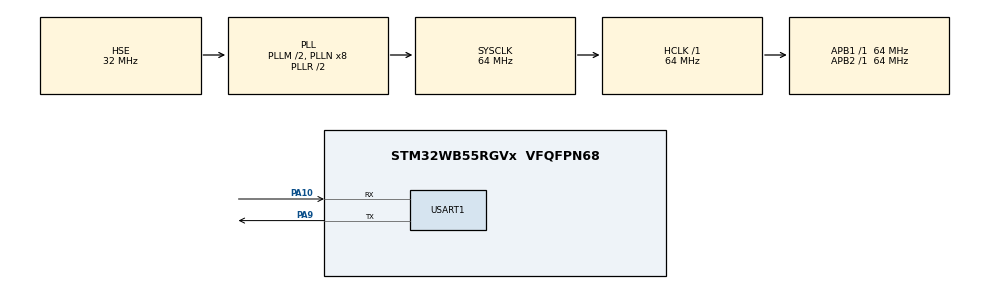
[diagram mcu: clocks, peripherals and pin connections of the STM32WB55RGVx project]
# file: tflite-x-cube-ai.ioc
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Mcu.Family=STM32WB
Mcu.Name=STM32WB55RGVx
Mcu.Package=VFQFPN68
NVIC.PriorityGroup=NVIC_PRIORITYGROUP_4
OSC_IN.GPIO_Label=RCC_OSC_IN
OSC_IN.Mode=HSE-External-Oscillator
OSC_IN.Signal=RCC_OSC_IN
OSC_OUT.GPIO_Label=RCC_OSC_OUT
OSC_OUT.Mode=HSE-External-Oscillator
OSC_OUT.Signal=RCC_OSC_OUT
P-NUCLEO-WB55-NUCLEO.BUTTON=1
P-NUCLEO-WB55-NUCLEO.BUTTON2=1
P-NUCLEO-WB55-NUCLEO.BUTTON3=1
P-NUCLEO-WB55-NUCLEO.LD1=true
P-NUCLEO-WB55-NUCLEO.LD2=true
P-NUCLEO-WB55-NUCLEO.LD3=true
P-NUCLEO-WB55-NUCLEO.VCP=false
PA10.Mode=Asynchronous
PA10.Signal=USART1_RX
PA11.GPIO_Label=USB_DM
PA11.Signal=USB_DM
PA12.GPIO_Label=USB_DP
PA12.Signal=USB_DP
PA13.GPIO_Label=JTMS
PA13.Signal=SYS_JTMS-SWDIO
PA14.GPIO_Label=JTCK
PA14.Signal=SYS_JTCK-SWCLK
PA9.Mode=Asynchronous
PA9.Signal=USART1_TX
PB3.GPIO_Label=JTDO
PB3.Signal=SYS_JTDO-SWO
PC13.GPIO_Label=SYS_WKUP2
PC13.Signal=SYS_WKUP2
PC14-OSC32_IN.GPIO_Label=RCC_OSC32_IN
PC14-OSC32_IN.Signal=RCC_OSC32_IN
PC15-OSC32_OUT.GPIO_Label=RCC_OSC32_OUT
PC15-OSC32_OUT.Signal=RCC_OSC32_OUT
ProjectManager.HeapSize=0x800
ProjectManager.StackSize=0x800
ProjectManager.TargetToolchain=STM32CubeIDE
RCC.ADCFreq_Value=64000000
RCC.AHB2CLKDivider=RCC_SYSCLK_DIV2
RCC.AHBFreq_Value=64000000
RCC.APB1Freq_Value=64000000
RCC.APB1TimFreq_Value=64000000
RCC.APB2Freq_Value=64000000
RCC.APB2TimFreq_Value=64000000
RCC.APB3Freq_Value=16000000
RCC.Cortex2_Div=SYSTICK_CLKSOURCE_HCLK_DIV8
RCC.CortexFreq_Value=64000000
RCC.HCLKFreq_Value=64000000
RCC.HSE_VALUE=32000000
RCC.HSI48_VALUE=48000000
RCC.HSI_VALUE=16000000
RCC.LPUART1CLockSelection=RCC_LPUART1CLKSOURCE_SYSCLK
RCC.LSE_VALUE=32768
RCC.MSIClockRange=RCC_MSIRANGE_10
RCC.PLLM=RCC_PLLM_DIV2
RCC.PLLSourceVirtual=RCC_PLLSOURCE_HSE
RCC.SMPSCLockSelection=RCC_SMPSCLKSOURCE_HSI
RCC.SMPSCLockSelectionVirtual=RCC_SMPSCLKSOURCE_HSI
RCC.SMPSCLockSelectionVirtualVirtual=RCC_SMPSCLKSOURCE_HSI
RCC.SMPSDivider=1
RCC.SYSCLKFreq_VALUE=64000000
RCC.SYSCLKSource=RCC_SYSCLKSOURCE_PLLCLK
RCC.USART1CLockSelection=RCC_USART1CLKSOURCE_SYSCLK
RCC.USBFreq_Value=64000000
RCC.VCOOutputFreq_Value=128000000
STMicroelectronics.X-CUBE-AI.10.2.0.ActivationBufferSizeList=5024
STMicroelectronics.X-CUBE-AI.10.2.0.ActivationBuffers=pool0
STMicroelectronics.X-CUBE-AI.10.2.0.ActivationNames=pool0
STMicroelectronics.X-CUBE-AI.10.2.0.ActivationSizes=AI_BASIC_MODEL_DATA_ACTIVATION_1_SIZE
STMicroelectronics.X-CUBE-AI.10.2.0.ApplicationCcDeviceJjApplication=ApplicationTemplate
STMicroelectronics.X-CUBE-AI.10.2.0.HeapSize=0x800
STMicroelectronics.X-CUBE-AI.10.2.0.InternalRamActivationBufferMaxSize=AI_BASIC_MODEL_DATA_ACTIVATIONS_SIZE
STMicroelectronics.X-CUBE-AI.10.2.0.MaximumNumberOfInputLayer=1
STMicroelectronics.X-CUBE-AI.10.2.0.MaximumNumberOfOutputLayer=1
STMicroelectronics.X-CUBE-AI.10.2.0.MaximumSizeOfInputLayer=1
STMicroelectronics.X-CUBE-AI.10.2.0.MaximumSizeOfOutputLayer=1
STMicroelectronics.X-CUBE-AI.10.2.0.ModelActualCompression-c29d578fcdd2ad290cb5f3d3d47015f156259ff803bf11daba03a2a641401ff9=0.0
STMicroelectronics.X-CUBE-AI.10.2.0.ModelCompression-c29d578fcdd2ad290cb5f3d3d47015f156259ff803bf11daba03a2a641401ff9=None
STMicroelectronics.X-CUBE-AI.10.2.0.ModelFlashOccupation-c29d578fcdd2ad290cb5f3d3d47015f156259ff803bf11daba03a2a641401ff9=415332
STMicroelectronics.X-CUBE-AI.10.2.0.ModelHashList=c29d578fcdd2ad290cb5f3d3d47015f156259ff803bf11daba03a2a641401ff9
STMicroelectronics.X-CUBE-AI.10.2.0.ModelKind-c29d578fcdd2ad290cb5f3d3d47015f156259ff803bf11daba03a2a641401ff9=TFLITE
STMicroelectronics.X-CUBE-AI.10.2.0.ModelMacc-c29d578fcdd2ad290cb5f3d3d47015f156259ff803bf11daba03a2a641401ff9=101898
STMicroelectronics.X-CUBE-AI.10.2.0.ModelName-c29d578fcdd2ad290cb5f3d3d47015f156259ff803bf11daba03a2a641401ff9=basic_model
STMicroelectronics.X-CUBE-AI.10.2.0.ModelNameList=basic_model
STMicroelectronics.X-CUBE-AI.10.2.0.ModelRamOccupation-c29d578fcdd2ad290cb5f3d3d47015f156259ff803bf11daba03a2a641401ff9=5024
STMicroelectronics.X-CUBE-AI.10.2.0.ModelStructureFile-c29d578fcdd2ad290cb5f3d3d47015f156259ff803bf11daba03a2a641401ff9=C\:\\Users\\jakub\\Desktop\\programming\\stm32\\ml-embedded\\digits-recognition-model/basic_model_converted.tflite
STMicroelectronics.X-CUBE-AI.10.2.0.ModelType-c29d578fcdd2ad290cb5f3d3d47015f156259ff803bf11daba03a2a641401ff9=STM32Cube.AI MCU runtime
STMicroelectronics.X-CUBE-AI.10.2.0.ReadyForCodeGeneration=true
STMicroelectronics.X-CUBE-AI.10.2.0.StackSize=0x800
STMicroelectronics.X-CUBE-AI.10.2.0.WorkingBufferStartAddrList=0xFFFFFFFF
STMicroelectronics.X-CUBE-AI.10.2.0.XAaCUBEAaAICcArtificialOoIntelligenceJjCore=true
STMicroelectronics.X-CUBE-AI.10.2.0.copyWeightToRam=false
STMicroelectronics.X-CUBE-AI.10.2.0.copyWeightToRam-c29d578fcdd2ad290cb5f3d3d47015f156259ff803bf11daba03a2a641401ff9=false
STMicroelectronics.X-CUBE-AI.10.2.0.customLayerConfigEnabled=false
STMicroelectronics.X-CUBE-AI.10.2.0.customLayerConfigEnabled-c29d578fcdd2ad290cb5f3d3d47015f156259ff803bf11daba03a2a641401ff9=false
STMicroelectronics.X-CUBE-AI.10.2.0.noOnnxIoTranspose=false
STMicroelectronics.X-CUBE-AI.10.2.0.noOnnxIoTranspose-c29d578fcdd2ad290cb5f3d3d47015f156259ff803bf11daba03a2a641401ff9=false
STMicroelectronics.X-CUBE-AI.10.2.0.useInputAllocation=true
STMicroelectronics.X-CUBE-AI.10.2.0.useInputAllocation-c29d578fcdd2ad290cb5f3d3d47015f156259ff803bf11daba03a2a641401ff9=true
STMicroelectronics.X-CUBE-AI.10.2.0.useOutputAllocation=true
STMicroelectronics.X-CUBE-AI.10.2.0.useOutputAllocation-c29d578fcdd2ad290cb5f3d3d47015f156259ff803bf11daba03a2a641401ff9=true
TIM16.Period=65536 - 1
TIM16.Prescaler=80 - 1
USART1.VirtualMode-Asynchronous=VM_ASYNC
VP_MEMORYMAP_VS_MEMORYMAP.Mode=CurAppReg
VP_P-NUCLEO-WB55-NUCLEO_VS_BSP_COMMON.Mode=COMMON
VP_STMicroelectronics.X-CUBE-AI_VS_ArtificialOoIntelligenceJjXAaCUBEAaAI_10.2.0.Mode=ArtificialOoIntelligenceJjXAaCUBEAaAI
VP_STMicroelectronics.X-CUBE-AI_VS_DeviceJjApplication_10.2.0.Mode=DeviceJjApplication
VP_TIM16_VS_ClockSourceINT.Mode=Enable_Timer
board=P-NUCLEO-WB55-NUCLEO

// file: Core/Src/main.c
/* USER CODE BEGIN Header */
/**
  ******************************************************************************
  * @file           : main.c
  * @brief          : Main program body
  ******************************************************************************
  * @attention
  *
  * Copyright (c) 2025 STMicroelectronics.
  * All rights reserved.
  *
  * This software is licensed under terms that can be found in the LICENSE file
  * in the root directory of this software component.
  * If no LICENSE file comes with this software, it is provided AS-IS.
  *
  ******************************************************************************
  */
/* USER CODE END Header */
#include "main.h"
#include "app_x-cube-ai.h"

/* USER CODE BEGIN Includes */
#include <string.h>
#include <stdio.h>

#include "ai_platform.h"
#include "ai_datatypes_defines.h"

#include "basic_model.h"
#include "basic_model_data.h"

/* USER CODE END Includes */

TIM_HandleTypeDef htim16;

UART_HandleTypeDef huart1;

/* USER CODE BEGIN PV */

uint8_t uart_rx_data[20] = {0};

uint8_t out[20] = {0};
uint16_t n_out = 0;

/* USER CODE END PV */

void SystemClock_Config(void);
void PeriphCommonClock_Config(void);
static void MX_GPIO_Init(void);
static void MX_TIM16_Init(void);
static void MX_USART1_UART_Init(void);

/* USER CODE BEGIN 0 */

void HAL_UART_RxCpltCallback(UART_HandleTypeDef* huart) {
	if (huart->Instance == USART1) {
		uart_rx_data[6] = '\0';

		n_out = snprintf((char*)out, 20 - 1, "Hello! %s\r\n", uart_rx_data);

		HAL_UART_Receive_IT(&huart1, uart_rx_data, 5);
	}
}

static ai_buffer *ai_input;
static ai_buffer *ai_output;

void ai_init(void) {
  ai_input = AI_BASIC_MODEL_IN;
  ai_output = AI_BASIC_MODEL_OUT;
}

static size_t buf_len = 0;
static char buf[4096];

/* USER CODE END 0 */

int main(void)
{

  /* MCU Configuration--------------------------------------------------------*/

  /* Reset of all peripherals, Initializes the Flash interface and the Systick. */
  HAL_Init();

  /* Configure the system clock */
  SystemClock_Config();

  /* Configure the peripherals common clocks */
  PeriphCommonClock_Config();

  /* Initialize all configured peripherals */
  MX_GPIO_Init();
  MX_TIM16_Init();
  MX_USART1_UART_Init();
  MX_X_CUBE_AI_Init();
  /* USER CODE BEGIN 2 */

  ai_error ai_err;
  ai_i32 nbatch;
  uint32_t timestamp;
  float y_val[10] = {0};
  AI_ALIGNED(4) ai_u8 activations[AI_BASIC_MODEL_DATA_ACTIVATIONS_SIZE];

  // Buffers used to store input and output tensors
  AI_ALIGNED(4) ai_i8 in_data[AI_BASIC_MODEL_IN_1_SIZE_BYTES];
  AI_ALIGNED(4) ai_i8 out_data[AI_BASIC_MODEL_OUT_1_SIZE_BYTES];

  // Pointer to our model
  ai_handle basic_model = AI_HANDLE_NULL;

  // Initialize wrapper structs that hold pointers to data and info about the
  // data (tensor height, width, channels)

  // Set working memory and get weights/biases from model
  ai_network_params ai_params = {
    AI_BASIC_MODEL_DATA_WEIGHTS(ai_basic_model_data_weights_get()),
    AI_BASIC_MODEL_DATA_ACTIVATIONS(activations)
  };

  // Set pointers wrapper structs to our data buffers
  ai_input[0].data = AI_HANDLE_PTR(in_data);
  ai_output[0].data = AI_HANDLE_PTR(out_data);

//  HAL_UART_Receive_IT(&huart1, uart_rx_data, 5);

  ai_err = ai_basic_model_create(&basic_model, AI_BASIC_MODEL_DATA_CONFIG);
  if (ai_err.type != AI_ERROR_NONE)
  {
    buf_len = sprintf(buf, "Error: could not create NN instance\r\n");
    HAL_UART_Transmit(&huart1, (uint8_t *)buf, buf_len, 100);
    while(1);
  }

  if (!ai_basic_model_init(basic_model, &ai_params))
  {
    buf_len = sprintf(buf, "Error: could not initialize NN\r\n");
    HAL_UART_Transmit(&huart1, (uint8_t *)buf, buf_len, 100);
    while(1);
  }

  /* USER CODE END 2 */

  /* Initialize leds */
  BSP_LED_Init(LED_BLUE);
  BSP_LED_Init(LED_GREEN);
  BSP_LED_Init(LED_RED);

  /* Initialize USER push-button, will be used to trigger an interrupt each time it's pressed.*/
  BSP_PB_Init(BUTTON_SW1, BUTTON_MODE_EXTI);
  BSP_PB_Init(BUTTON_SW2, BUTTON_MODE_EXTI);
  BSP_PB_Init(BUTTON_SW3, BUTTON_MODE_EXTI);

  /* Infinite loop */
  /* USER CODE BEGIN WHILE */

  while (1)
  {
	    for (uint32_t i = 0; i < AI_BASIC_MODEL_IN_1_SIZE; i++)
	    {
	      ((ai_float *)in_data)[i] = (ai_float)2.0f;
	    }

	    // Get current timestamp
//	    timestamp = htim16.Instance->CNT;

	    // Perform inference
	    nbatch = ai_basic_model_run(basic_model, &ai_input[0], &ai_output[0]);
	    if (nbatch != 1) {
	      buf_len = sprintf(buf, "Error: could not run inference\r\n");
	      HAL_UART_Transmit(&huart1, (uint8_t *)buf, buf_len, 100);
	    }

	    for (size_t i = 0; i < 10; i++){
	    	y_val[i] = *(out_data + i);
	    }

	    buf_len = sprintf(buf,
	                      "0: %f 1: %f 2: %f 3: %f 4: %f 5: %f 6: %f 7: %f 8: %f 9: %f\r\n",
	                      y_val[0],
	                      y_val[1],
	                      y_val[2],
	                      y_val[3],
	                      y_val[4],
	                      y_val[5],
	                      y_val[6],
	                      y_val[7],
	                      y_val[8],
	                      y_val[9]
	    						);

	    HAL_UART_Transmit(&huart1, (uint8_t *)buf, buf_len, 100);

//		HAL_UART_Transmit(&huart1, (uint8_t*)"dupa\r\n", strlen("dupa\r\n"), 1000);
		HAL_Delay(1000);
	  /*
	  if (n_out > 0){
		HAL_UART_Transmit(&huart1, out, n_out, HAL_MAX_DELAY);
		n_out = 0;
	  }
	   */

    /* USER CODE END WHILE */

  MX_X_CUBE_AI_Process();
  }
}

void SystemClock_Config(void)
{
  RCC_OscInitTypeDef RCC_OscInitStruct = {0};
  RCC_ClkInitTypeDef RCC_ClkInitStruct = {0};

  /** Configure the main internal regulator output voltage
  */
  __HAL_PWR_VOLTAGESCALING_CONFIG(PWR_REGULATOR_VOLTAGE_SCALE1);

  /** Initializes the RCC Oscillators according to the specified parameters
  * in the RCC_OscInitTypeDef structure.
  */
  RCC_OscInitStruct.OscillatorType = RCC_OSCILLATORTYPE_HSI|RCC_OSCILLATORTYPE_HSE;
  RCC_OscInitStruct.HSEState = RCC_HSE_ON;
  RCC_OscInitStruct.HSIState = RCC_HSI_ON;
  RCC_OscInitStruct.HSICalibrationValue = RCC_HSICALIBRATION_DEFAULT;
  RCC_OscInitStruct.PLL.PLLState = RCC_PLL_ON;
  RCC_OscInitStruct.PLL.PLLSource = RCC_PLLSOURCE_HSE;
  RCC_OscInitStruct.PLL.PLLM = RCC_PLLM_DIV2;
  RCC_OscInitStruct.PLL.PLLN = 8;
  RCC_OscInitStruct.PLL.PLLP = RCC_PLLP_DIV2;
  RCC_OscInitStruct.PLL.PLLR = RCC_PLLR_DIV2;
  RCC_OscInitStruct.PLL.PLLQ = RCC_PLLQ_DIV2;
  if (HAL_RCC_OscConfig(&RCC_OscInitStruct) != HAL_OK)
  {
    Error_Handler();
  }

  /** Configure the SYSCLKSource, HCLK, PCLK1 and PCLK2 clocks dividers
  */
  RCC_ClkInitStruct.ClockType = RCC_CLOCKTYPE_HCLK4|RCC_CLOCKTYPE_HCLK2
                              |RCC_CLOCKTYPE_HCLK|RCC_CLOCKTYPE_SYSCLK
                              |RCC_CLOCKTYPE_PCLK1|RCC_CLOCKTYPE_PCLK2;
  RCC_ClkInitStruct.SYSCLKSource = RCC_SYSCLKSOURCE_PLLCLK;
  RCC_ClkInitStruct.AHBCLKDivider = RCC_SYSCLK_DIV1;
  RCC_ClkInitStruct.APB1CLKDivider = RCC_HCLK_DIV1;
  RCC_ClkInitStruct.APB2CLKDivider = RCC_HCLK_DIV1;
  RCC_ClkInitStruct.AHBCLK2Divider = RCC_SYSCLK_DIV2;
  RCC_ClkInitStruct.AHBCLK4Divider = RCC_SYSCLK_DIV1;

  if (HAL_RCC_ClockConfig(&RCC_ClkInitStruct, FLASH_LATENCY_3) != HAL_OK)
  {
    Error_Handler();
  }
}

void PeriphCommonClock_Config(void)
{
  RCC_PeriphCLKInitTypeDef PeriphClkInitStruct = {0};

  /** Initializes the peripherals clock
  */
  PeriphClkInitStruct.PeriphClockSelection = RCC_PERIPHCLK_SMPS;
  PeriphClkInitStruct.SmpsClockSelection = RCC_SMPSCLKSOURCE_HSI;
  PeriphClkInitStruct.SmpsDivSelection = RCC_SMPSCLKDIV_RANGE0;

  if (HAL_RCCEx_PeriphCLKConfig(&PeriphClkInitStruct) != HAL_OK)
  {
    Error_Handler();
  }
}

static void MX_TIM16_Init(void)
{

  htim16.Instance = TIM16;
  htim16.Init.Prescaler = 80 - 1;
  htim16.Init.CounterMode = TIM_COUNTERMODE_UP;
  htim16.Init.Period = 65536 - 1;
  htim16.Init.ClockDivision = TIM_CLOCKDIVISION_DIV1;
  htim16.Init.RepetitionCounter = 0;
  htim16.Init.AutoReloadPreload = TIM_AUTORELOAD_PRELOAD_DISABLE;
  if (HAL_TIM_Base_Init(&htim16) != HAL_OK)
  {
    Error_Handler();
  }

}

static void MX_USART1_UART_Init(void)
{

  huart1.Instance = USART1;
  huart1.Init.BaudRate = 115200;
  huart1.Init.WordLength = UART_WORDLENGTH_8B;
  huart1.Init.StopBits = UART_STOPBITS_1;
  huart1.Init.Parity = UART_PARITY_NONE;
  huart1.Init.Mode = UART_MODE_TX_RX;
  huart1.Init.HwFlowCtl = UART_HWCONTROL_NONE;
  huart1.Init.OverSampling = UART_OVERSAMPLING_16;
  huart1.Init.OneBitSampling = UART_ONE_BIT_SAMPLE_DISABLE;
  huart1.Init.ClockPrescaler = UART_PRESCALER_DIV1;
  huart1.AdvancedInit.AdvFeatureInit = UART_ADVFEATURE_NO_INIT;
  if (HAL_UART_Init(&huart1) != HAL_OK)
  {
    Error_Handler();
  }
  if (HAL_UARTEx_SetTxFifoThreshold(&huart1, UART_TXFIFO_THRESHOLD_1_8) != HAL_OK)
  {
    Error_Handler();
  }
  if (HAL_UARTEx_SetRxFifoThreshold(&huart1, UART_RXFIFO_THRESHOLD_1_8) != HAL_OK)
  {
    Error_Handler();
  }
  if (HAL_UARTEx_DisableFifoMode(&huart1) != HAL_OK)
  {
    Error_Handler();
  }

}

static void MX_GPIO_Init(void)
{
  GPIO_InitTypeDef GPIO_InitStruct = {0};

  /* GPIO Ports Clock Enable */
  __HAL_RCC_GPIOC_CLK_ENABLE();
  __HAL_RCC_GPIOA_CLK_ENABLE();
  __HAL_RCC_GPIOB_CLK_ENABLE();

  /*Configure GPIO pins : USB_DM_Pin USB_DP_Pin */
  GPIO_InitStruct.Pin = USB_DM_Pin|USB_DP_Pin;
  GPIO_InitStruct.Mode = GPIO_MODE_AF_PP;
  GPIO_InitStruct.Pull = GPIO_NOPULL;
  GPIO_InitStruct.Speed = GPIO_SPEED_FREQ_LOW;
  GPIO_InitStruct.Alternate = GPIO_AF10_USB;
  HAL_GPIO_Init(GPIOA, &GPIO_InitStruct);

}

void Error_Handler(void)
{
  __disable_irq();
  while (1)
  {
  }
}
